# nrf7120E_enga_application register map
Vendor: Nordic Semiconductor; Series: nrf71; File version: 1
CPU: CM33 r0p4, little endian, MPU, FPU, 3 interrupt priority bits, 270 interrupts, 4 SAU regions
Registers are 32-bit, read-write, reset 0x0 unless marked. A register's access mark holds for its fields unless they carry their own. Offsets are from the block's base; [hi:lo] are bit positions; 'fields as' and 'values as' point back to an identical list.

## GLOBAL_KMU_S — Key management unit
Base 0x50049000
0x00 TASKS_PROVISION wo — Provision key slot
  [0] TASKS_PROVISION
    1=Trigger task
0x04 TASKS_PUSH wo — Push key slot
  [0] TASKS_PUSH
    1=Trigger task
0x08 TASKS_REVOKE wo — Revoke key slot
  [0] TASKS_REVOKE
    1=Trigger task
0x0C TASKS_READMETADATA wo — Read key slot metadata into METADATA register
  [0] TASKS_READMETADATA
    1=Trigger task
0x10 TASKS_PUSHBLOCK wo — Block only the PUSH operation of a key slot, preventing the key slot from being PUSHED until next reset. The task is kept for backwards compatibility.
  [0] TASKS_PUSHBLOCK
    1=Trigger task
0x14 TASKS_BLOCK wo — Block the PROVISION, PUSH, and REVOKE operations of a key slot, preventing the key slot from being PROVISIONED, PUSHED, or REVOKED until next reset
  [0] TASKS_BLOCK
    1=Trigger task
0x100 EVENTS_PROVISIONED — Key slot successfully provisioned
  [0] EVENTS_PROVISIONED
    0=NotGenerated (Event not generated); 1=Generated (Event generated)
0x104 EVENTS_PUSHED — Key slot successfully pushed
  [0] EVENTS_PUSHED
    values as EVENTS_PROVISIONED.EVENTS_PROVISIONED
0x108 EVENTS_REVOKED — Key slot has been revoked and can no longer be used
  [0] EVENTS_REVOKED
    values as EVENTS_PROVISIONED.EVENTS_PROVISIONED
0x10C EVENTS_ERROR — Error generated during PROVISION, PUSH, READMETADATA or REVOKE operations. Triggering the PROVISION, PUSH and REVOKE tasks on a BLOCKED keyslot will also generate this event.
  [0] EVENTS_ERROR
    values as EVENTS_PROVISIONED.EVENTS_PROVISIONED
0x110 EVENTS_METADATAREAD — Key slot metadata has been read into METADATA register
  [0] EVENTS_METADATAREAD
    values as EVENTS_PROVISIONED.EVENTS_PROVISIONED
0x114 EVENTS_PUSHBLOCKED — The PUSHBLOCK operation was successful. The event is kept for backwards compatibility.
  [0] EVENTS_PUSHBLOCKED
    values as EVENTS_PROVISIONED.EVENTS_PROVISIONED
0x118 EVENTS_BLOCKED — The BLOCK operation was successful
  [0] EVENTS_BLOCKED
    values as EVENTS_PROVISIONED.EVENTS_PROVISIONED
0x400 STATUS ro — KMU status register
  [0] STATUS — KMU status
    0=Ready (KMU is ready for new operation); 1=Busy (KMU is busy, an operation is in progress)
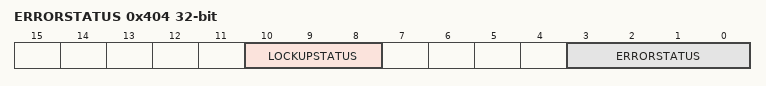
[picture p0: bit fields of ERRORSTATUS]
0x404 ERRORSTATUS ro — Error status and cause information
  [10:8] LOCKUPSTATUS — Status on KMU lockup
    0=NoLockup (KMU is not in lockup state); 1=LockupPush (KMU is in lockup state due to a bus fault during TASKS_PUSH); 2=LockupProvision (KMU is in lockup state due to a bus fault during TASKS_PROVISION); 3=LockupRevoke (KMU is in lockup state due to a bus fault during TASKS_REVOKE); 4=LockupReadmeta (KMU is in lockup state due to a bus fault during TASKS_READMETADATA)
  [3:0] ERRORSTATUS — Error information for last KMU operation
    0=NoError (The last KMU operation had no errors); 1=ProvAlreadyProv (TASKS_PROVISION failed due to keyslot already provisioned); 2=ProvSrcError (TASKS_PROVISION failed due to illegal SRC); 3=ProvDestError (TASKS_PROVISION failed due to illegal DEST); 4=PushNotProv (TASKS_PUSH failed due to keyslot revoked or not provisioned); 5=RevokeNotProv (TASKS_REVOKE failed due to keyslot already revoked, not provisioned or LOCKED revocation policy); 6=ReadmetaNotProv (TASKS_READMETADATA failed due to keyslot revoked or not provisioned); 7=KeyslotBlocked (Failed TASKS_PROVISION, TASKS_PUSH or TASKS_REVOKE due to keyslot blocked); 8=KeyslotPushblocked (Failed TASKS_PUSH due to keyslot pushblocked)
0x500 KEYSLOT — Select key slot to operate on
  [7:0] ID — Select key slot ID to provision, push, read METADATA, revoke or block when the corresponding task is triggered.
0x504 SRC — Source address for provisioning
  [31:0] SRC — Source address for TASKS_PROVISION.
0x508 METADATA — Key slot metadata as read by TASKS_READMETADATA.
  [31:0] METADATA — Read metadata.
0x50C METADATAEXT — Second word of key slot metadata as read by TASKS_READMETADATA.
  [31:0] METADATAEXT — Read metadata.
